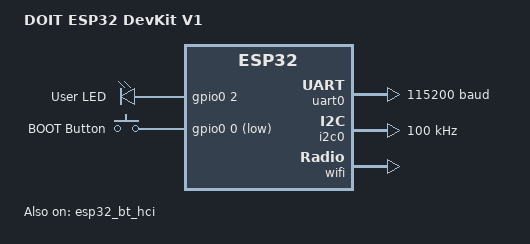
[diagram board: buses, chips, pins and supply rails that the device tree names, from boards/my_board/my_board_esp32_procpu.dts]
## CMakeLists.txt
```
cmake_minimum_required(VERSION 3.20.0)

list(APPEND BOARD_ROOT ${CMAKE_CURRENT_SOURCE_DIR})

find_package(Zephyr REQUIRED HINTS $ENV{ZEPHYR_BASE})
project(cboard2)

target_sources(app PRIVATE src/main.c)
```

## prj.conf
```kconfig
CONFIG_PRINTK=y
CONFIG_CONSOLE=y
```

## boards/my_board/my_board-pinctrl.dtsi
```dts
/*
 * SPDX-License-Identifier: Apache-2.0
 */

#include <zephyr/dt-bindings/pinctrl/esp32-pinctrl.h>

&pinctrl {
        uart0_default: uart0_default {
                group1 {
                        pinmux = <UART0_TX_GPIO1>;
                        output-high;
                };

                group2 {
                        pinmux = <UART0_RX_GPIO3>;
                        bias-pull-up;
                };
        };

        uart2_default: uart2_default {
                group1 {
                        pinmux = <UART2_TX_GPIO17>;
                };

                group2 {
                        pinmux = <UART2_RX_GPIO16>;
                        bias-pull-up;
                };
        };

        spim2_default: spim2_default {
                group1 {
                        pinmux = <SPIM2_MISO_GPIO12>,
                                 <SPIM2_SCLK_GPIO14>,
                                 <SPIM2_CSEL_GPIO15>;
                };

                group2 {
                        pinmux = <SPIM2_MOSI_GPIO13>;
                        output-low;
                };
        };

        spim3_default: spim3_default {
                group1 {
                        pinmux = <SPIM3_MISO_GPIO19>,
                                 <SPIM3_SCLK_GPIO18>,
                                 <SPIM3_CSEL_GPIO5>;
                };

                group2 {
                        pinmux = <SPIM3_MOSI_GPIO23>;
                        output-low;
                };
        };

        i2c0_default: i2c0_default {
                group1 {
                        pinmux = <I2C0_SDA_GPIO21>,
                                 <I2C0_SCL_GPIO22>;
                        bias-pull-up;
                        drive-open-drain;
                        output-high;
                };
        };

        i2s0_default: i2s0_default {
                group1 {
                        pinmux = <I2S0_O_WS_GPIO25>,
                                 <I2S0_O_BCK_GPIO26>,
                                 <I2S0_O_SD_GPIO27>,
                                 <I2S0_I_WS_GPIO33>,
                                 <I2S0_I_BCK_GPIO32>;
                        output-enable;
                };

                group2 {
                        pinmux = <I2S0_I_SD_GPIO35>;
                        input-enable;
                };
        };
};
```

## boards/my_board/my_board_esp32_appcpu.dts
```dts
/dts-v1/;

#include <espressif/esp32/esp32_appcpu.dtsi>
#include <espressif/partitions_0x1000_amp.dtsi>

/ {
        model = "My Custom ESP32 Board APPCPU";
        compatible = "custom,my_board";

        chosen {
                zephyr,sram = &sram1;
                zephyr,ipc_shm = &shm0;
                zephyr,ipc = &ipm0;
                zephyr,flash = &flash0;
                zephyr,code-partition = &slot0_appcpu_partition;
        };
};

&ipm0 {
        status = "okay";
};

&trng0 {
        status = "okay";
};
```

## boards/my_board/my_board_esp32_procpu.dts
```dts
/*
 * SPDX-License-Identifier: Apache-2.0
 */

/dts-v1/;

#include <espressif/esp32/esp32_wrover_e_n4r8.dtsi>
#include <espressif/partitions_0x1000_amp.dtsi>
#include <zephyr/dt-bindings/input/input-event-codes.h>
#include "my_board-pinctrl.dtsi"
/ {
        model = "DOIT ESP32 DevKit V1";
        compatible = "doit,esp32-devkit-v1";

        aliases {
                uart-0 = &uart0;
                i2c-0 = &i2c0;
                sw0 = &button0;
                led0 = &blue_led;
                watchdog0 = &wdt0;
        };

        leds {
                compatible = "gpio-leds";

                blue_led: blue_led {
                        gpios = <&gpio0 2 GPIO_ACTIVE_HIGH>;
                        label = "User LED";
                };
        };

        buttons {
                compatible = "gpio-keys";

                button0: button_0 {
                        gpios = <&gpio0 0 (GPIO_PULL_UP | GPIO_ACTIVE_LOW)>;
                        label = "BOOT Button";
                        zephyr,code = <INPUT_KEY_0>;
                };
        };

        chosen {
                zephyr,sram = &sram1;
                zephyr,console = &uart0;
                zephyr,shell-uart = &uart0;
                zephyr,flash = &flash0;
                zephyr,code-partition = &slot0_partition;
                zephyr,bt-hci = &esp32_bt_hci;
        };
};

&uart0 {
    status = "okay";
    current-speed = <115200>;
    pinctrl-0 = <&uart0_default>;
    pinctrl-names = "default";
};

&gpio0 {
        status = "okay";
};

&gpio1 {
        status = "okay";
};

&i2c0 {
    status = "okay";
    clock-frequency = <I2C_BITRATE_STANDARD>;
    pinctrl-0 = <&i2c0_default>;
    pinctrl-names = "default";
};

&esp32_bt_hci {
        status = "okay";
};

&wifi {
        status = "okay";
};
```

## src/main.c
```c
#include <zephyr/kernel.h>

int main(void)
{
    printk("Hello World! %s\n", CONFIG_BOARD_TARGET);
    return 0;
}
```
